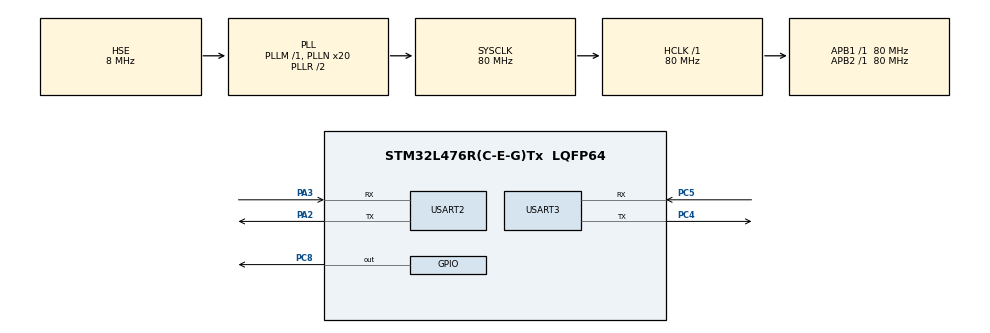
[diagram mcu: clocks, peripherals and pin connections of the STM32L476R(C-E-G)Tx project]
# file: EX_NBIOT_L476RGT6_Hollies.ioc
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Dma.Request0=USART2_RX
Dma.Request1=USART3_RX
Dma.USART2_RX.0.Direction=DMA_PERIPH_TO_MEMORY
Dma.USART2_RX.0.Instance=DMA1_Channel6
Dma.USART2_RX.0.MemDataAlignment=DMA_MDATAALIGN_BYTE
Dma.USART2_RX.0.MemInc=DMA_MINC_ENABLE
Dma.USART2_RX.0.Mode=DMA_NORMAL
Dma.USART2_RX.0.PeriphDataAlignment=DMA_PDATAALIGN_BYTE
Dma.USART2_RX.0.PeriphInc=DMA_PINC_DISABLE
Dma.USART2_RX.0.Priority=DMA_PRIORITY_LOW
Dma.USART3_RX.1.Direction=DMA_PERIPH_TO_MEMORY
Dma.USART3_RX.1.Instance=DMA1_Channel3
Dma.USART3_RX.1.MemDataAlignment=DMA_MDATAALIGN_BYTE
Dma.USART3_RX.1.MemInc=DMA_MINC_ENABLE
Dma.USART3_RX.1.Mode=DMA_NORMAL
Dma.USART3_RX.1.PeriphDataAlignment=DMA_PDATAALIGN_BYTE
Dma.USART3_RX.1.PeriphInc=DMA_PINC_DISABLE
Dma.USART3_RX.1.Priority=DMA_PRIORITY_LOW
Mcu.Family=STM32L4
Mcu.Name=STM32L476R(C-E-G)Tx
Mcu.Package=LQFP64
NVIC.DMA1_Channel3_IRQn=true\:0\:0\:false\:false\:true\:false\:true\:true
NVIC.DMA1_Channel6_IRQn=true\:0\:0\:false\:false\:true\:false\:true\:true
NVIC.PriorityGroup=NVIC_PRIORITYGROUP_4
NVIC.TIM1_UP_TIM16_IRQn=true\:0\:0\:false\:false\:true\:true\:true\:true
NVIC.TIM2_IRQn=true\:0\:0\:false\:false\:true\:true\:true\:true
NVIC.TIM6_DAC_IRQn=true\:15\:0\:false\:false\:true\:false\:true\:true
NVIC.TimeBase=TIM6_DAC_IRQn
NVIC.TimeBaseIP=TIM6
NVIC.USART2_IRQn=true\:0\:0\:false\:false\:true\:true\:true\:true
NVIC.USART3_IRQn=true\:0\:0\:false\:false\:true\:true\:true\:true
PA13\ (JTMS-SWDIO).Mode=Serial_Wire
PA13\ (JTMS-SWDIO).Signal=SYS_JTMS-SWDIO
PA14\ (JTCK-SWCLK).Mode=Serial_Wire
PA14\ (JTCK-SWCLK).Signal=SYS_JTCK-SWCLK
PA2.Mode=Asynchronous
PA2.Signal=USART2_TX
PA3.Mode=Asynchronous
PA3.Signal=USART2_RX
PC14-OSC32_IN\ (PC14).Mode=LSE-External-Oscillator
PC14-OSC32_IN\ (PC14).Signal=RCC_OSC32_IN
PC15-OSC32_OUT\ (PC15).Mode=LSE-External-Oscillator
PC15-OSC32_OUT\ (PC15).Signal=RCC_OSC32_OUT
PC4.Mode=Asynchronous
PC4.Signal=USART3_TX
PC5.Mode=Asynchronous
PC5.Signal=USART3_RX
PC8.GPIO_PuPd=GPIO_PULLUP
PC8.PinState=GPIO_PIN_SET
PC8.Signal=GPIO_Output
PH0-OSC_IN\ (PH0).Mode=HSE-External-Oscillator
PH0-OSC_IN\ (PH0).Signal=RCC_OSC_IN
PH1-OSC_OUT\ (PH1).Mode=HSE-External-Oscillator
PH1-OSC_OUT\ (PH1).Signal=RCC_OSC_OUT
ProjectManager.HeapSize=0x200
ProjectManager.StackSize=0x400
ProjectManager.TargetToolchain=STM32CubeIDE
RCC.ADCFreq_Value=32000000
RCC.AHBFreq_Value=80000000
RCC.APB1Freq_Value=80000000
RCC.APB1TimFreq_Value=80000000
RCC.APB2Freq_Value=80000000
RCC.APB2TimFreq_Value=80000000
RCC.CortexFreq_Value=80000000
RCC.HCLKFreq_Value=80000000
RCC.HSE_VALUE=8000000
RCC.HSI_VALUE=16000000
RCC.MSI_VALUE=4000000
RCC.PLLN=20
RCC.PLLSourceVirtual=RCC_PLLSOURCE_HSE
RCC.SYSCLKFreq_VALUE=80000000
RCC.SYSCLKSource=RCC_SYSCLKSOURCE_PLLCLK
RCC.USBFreq_Value=32000000
RCC.VCOOutputFreq_Value=160000000
TIM1.Period=10000-1
TIM1.Prescaler=80-1
TIM2.Period=80000-1
USART2.VirtualMode-Asynchronous=VM_ASYNC
USART3.VirtualMode-Asynchronous=VM_ASYNC
VP_SYS_VS_tim6.Mode=TIM6
VP_TIM1_VS_ClockSourceINT.Mode=Internal
VP_TIM2_VS_ClockSourceINT.Mode=Internal
board=custom

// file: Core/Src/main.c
/* USER CODE BEGIN Header */
/**
 ******************************************************************************
 * @file           : main.c
 * @brief          : Main program body
 ******************************************************************************
 * @attention
 *
 * Copyright (c) 2024 STMicroelectronics.
 * All rights reserved.
 *
 * This software is licensed under terms that can be found in the LICENSE file
 * in the root directory of this software component.
 * If no LICENSE file comes with this software, it is provided AS-IS.
 *
 ******************************************************************************
 */
/* USER CODE END Header */
#include "main.h"
#include "dma.h"
#include "tim.h"
#include "usart.h"
#include "gpio.h"

/* USER CODE BEGIN Includes */
#include <string.h>
/* USER CODE END Includes */

void SystemClock_Config(void);

/* USER CODE BEGIN 0 */
uint8_t rx1_data[512];
uint8_t rx2_data[512];
/* USER CODE END 0 */

int main(void)
{

  /* MCU Configuration--------------------------------------------------------*/

  /* Reset of all peripherals, Initializes the Flash interface and the Systick. */
  HAL_Init();

  /* Configure the system clock */
  SystemClock_Config();

  /* Initialize all configured peripherals */
  MX_GPIO_Init();
  MX_DMA_Init();
  MX_TIM1_Init();
  MX_USART2_UART_Init();
  MX_TIM2_Init();
  MX_USART3_UART_Init();
  /* USER CODE BEGIN 2 */
  HAL_GPIO_WritePin(GPIOC, GPIO_PIN_8, GPIO_PIN_SET);
  HAL_UARTEx_ReceiveToIdle_DMA(&huart3, rx1_data, sizeof(rx1_data)); // 接收数据空闲中断
  HAL_UARTEx_ReceiveToIdle_DMA(&huart2, rx2_data, sizeof(rx2_data)); // 接收数据空闲中断
  /* USER CODE END 2 */

  /* Infinite loop */
  while (1)
  {

  }
}

void SystemClock_Config(void)
{
  RCC_OscInitTypeDef RCC_OscInitStruct = {0};
  RCC_ClkInitTypeDef RCC_ClkInitStruct = {0};

  /** Configure the main internal regulator output voltage
  */
  if (HAL_PWREx_ControlVoltageScaling(PWR_REGULATOR_VOLTAGE_SCALE1) != HAL_OK)
  {
    Error_Handler();
  }

  /** Initializes the RCC Oscillators according to the specified parameters
  * in the RCC_OscInitTypeDef structure.
  */
  RCC_OscInitStruct.OscillatorType = RCC_OSCILLATORTYPE_HSE;
  RCC_OscInitStruct.HSEState = RCC_HSE_ON;
  RCC_OscInitStruct.PLL.PLLState = RCC_PLL_ON;
  RCC_OscInitStruct.PLL.PLLSource = RCC_PLLSOURCE_HSE;
  RCC_OscInitStruct.PLL.PLLM = 1;
  RCC_OscInitStruct.PLL.PLLN = 20;
  RCC_OscInitStruct.PLL.PLLP = RCC_PLLP_DIV7;
  RCC_OscInitStruct.PLL.PLLQ = RCC_PLLQ_DIV2;
  RCC_OscInitStruct.PLL.PLLR = RCC_PLLR_DIV2;
  if (HAL_RCC_OscConfig(&RCC_OscInitStruct) != HAL_OK)
  {
    Error_Handler();
  }

  /** Initializes the CPU, AHB and APB buses clocks
  */
  RCC_ClkInitStruct.ClockType = RCC_CLOCKTYPE_HCLK|RCC_CLOCKTYPE_SYSCLK
                              |RCC_CLOCKTYPE_PCLK1|RCC_CLOCKTYPE_PCLK2;
  RCC_ClkInitStruct.SYSCLKSource = RCC_SYSCLKSOURCE_PLLCLK;
  RCC_ClkInitStruct.AHBCLKDivider = RCC_SYSCLK_DIV1;
  RCC_ClkInitStruct.APB1CLKDivider = RCC_HCLK_DIV1;
  RCC_ClkInitStruct.APB2CLKDivider = RCC_HCLK_DIV1;

  if (HAL_RCC_ClockConfig(&RCC_ClkInitStruct, FLASH_LATENCY_4) != HAL_OK)
  {
    Error_Handler();
  }
}

/* USER CODE BEGIN 4 */
// 接收空闲中断
void HAL_UARTEx_RxEventCallback(UART_HandleTypeDef *huart, uint16_t Size)
{
  if (huart->Instance == USART3)
  {
    HAL_UART_Transmit(&huart2, rx1_data, Size, 1000);
    HAL_UARTEx_ReceiveToIdle_DMA(&huart3, rx1_data, sizeof(rx1_data)); // 重新启动接收
  }
  if (huart->Instance == USART2)
  {
    HAL_UART_Transmit(&huart3, rx2_data, Size, 1000);
    HAL_UARTEx_ReceiveToIdle_DMA(&huart2, rx2_data, sizeof(rx2_data)); // 重新启动接收
  }
}
/* USER CODE END 4 */

void HAL_TIM_PeriodElapsedCallback(TIM_HandleTypeDef *htim)
{
  if (htim->Instance == TIM6) {
    HAL_IncTick();
  }
  /* USER CODE BEGIN Callback 1 */
  if (htim->Instance == TIM2)
  {
  }
  /* USER CODE END Callback 1 */
}

void Error_Handler(void)
{
  __disable_irq();
  while (1)
  {
  }
}
